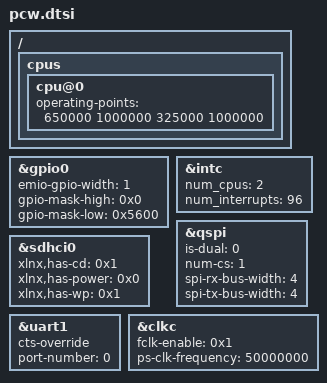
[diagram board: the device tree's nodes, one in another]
/*
 * CAUTION: This file is automatically generated by Xilinx.
 * Version: XSCT 2019.2.1
 * Today is: Sat Feb 15 18:48:21 2020
 */


/ {
	cpus {
		cpu@0 {
			operating-points = <650000 1000000 325000 1000000>;
		};
	};
};
&gpio0 {
	emio-gpio-width = <1>;
	gpio-mask-high = <0x0>;
	gpio-mask-low = <0x5600>;
};
&intc {
	num_cpus = <2>;
	num_interrupts = <96>;
};
&qspi {
	is-dual = <0>;
	num-cs = <1>;
	spi-rx-bus-width = <4>;
	spi-tx-bus-width = <4>;
	status = "okay";
};
&sdhci0 {
	status = "okay";
	xlnx,has-cd = <0x1>;
	xlnx,has-power = <0x0>;
	xlnx,has-wp = <0x1>;
};
&uart1 {
	cts-override ;
	device_type = "serial";
	port-number = <0>;
	status = "okay";
};
&clkc {
	fclk-enable = <0x1>;
	ps-clk-frequency = <50000000>;
};
